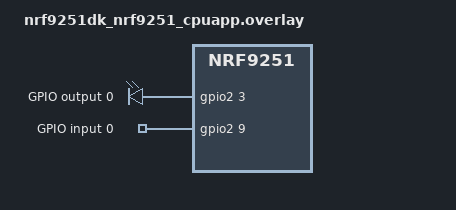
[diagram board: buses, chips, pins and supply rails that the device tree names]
/ {
	aliases {
		led = &led0;
		out0 = &output0;
		in0 = &input0;
	};

	outputs {
		compatible = "gpio-leds";

		output0: output_0 {
			gpios = <&gpio2 3 GPIO_ACTIVE_HIGH>;
			label = "GPIO output 0";
		};
	};

	inputs {
		compatible = "gpio-keys";

		input0: input_0 {
			gpios = <&gpio2 9 GPIO_ACTIVE_HIGH>;
			label = "GPIO input 0";
		};
	};
};

&gpio2 {
	status = "okay";
};

&gpiote130 {
	status = "okay";
};
